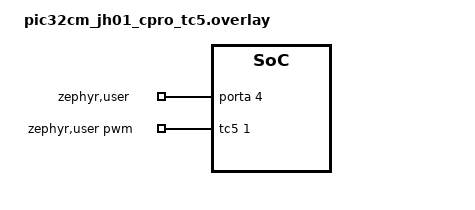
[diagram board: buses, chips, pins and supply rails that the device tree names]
/*
 * SPDX-FileCopyrightText: Copyright 2026 Microchip Technology Inc.
 * SPDX-License-Identifier: Apache-2.0
 */

/* connect PA5 to PA4 */

#define PWM_NODE    tc5
#define PWM_PINCTRL tc5_pwm_default
#include "mchp_pwm_loopback_support.dtsi"

/ {
	zephyr,user {
		pwms = <&tc5 1 PWM_MSEC(20) 0>;
		gpios = <&porta 4 GPIO_ACTIVE_HIGH>;
	};
};

&porta {
	status = "okay";
};

&pinctrl {
	tc5_pwm_default: tc5_pwm_default {
		group1 {
			pinmux = <PA5F_TC5_WO1>;
		};
	};
};
